# RN831X_RN861X_MCU register map
File version: v0.0.1
CPU: RN831X_RN861X_MCU r1p0, little endian, MPU, no FPU
Registers are 32-bit, read-write, reset 0x0 unless marked. A register's access mark holds for its fields unless they carry their own. Offsets are from the block's base; [hi:lo] are bit positions.

## LCSS_VCC_CORE0 — LCSS_VCC Module core0
Base 0x2010C000
0x00 PSW0 access not given — Security key register 0
  [15:0] PSW — Managed registers include LCSS_EN/LCSS_ASWH/LCSS_CTRL/LCSS_RCL_OS/LCSS_HFDLA_TH/LCSS_LFDLA_TH/LCSS_IE
0x04 PSW1 access not given — Security key register 1
  [15:0] PSW — Managed registers include LCSS_CLKSWH
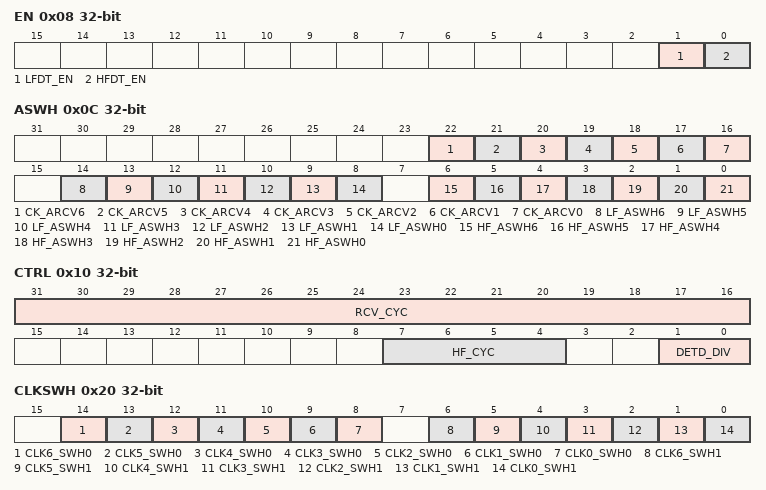
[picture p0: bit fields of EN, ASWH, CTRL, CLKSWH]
0x08 EN — Enable register
  [1] LFDT_EN — Low frequency abnormal detection enable
  [0] HFDT_EN — High frequency abnormal detection enable
0x0C ASWH — Auto switch configuration register
  [22] CK_ARCV6 — (System clock: LOSC to RCL) Enable automatic switch to source clock in normal frequency
  [21] CK_ARCV5 — (Infrared Clock: LOSC to RCL) Enable automatic switch to source clock in normal frequency
  [20] CK_ARCV4 — (LCD Clock: LOSC to RCL) Enable automatic switch to source clock in normal frequency
  [19] CK_ARCV3 — (LPUART Clock: LOSC to RCL) Enable automatic switch to source clock in normal frequency
  [18] CK_ARCV2 — (KBI Clock: LOSC to RCL) Enable automatic switch to source clock in normal frequency
  [17] CK_ARCV1 — (PLL source: LOSC to RCL) Enable automatic switch to source clock in normal frequency
  [16] CK_ARCV0 — (System clock: PLL to RCH) Enable automatic switch to backup clock in low frequency abnormality
  [14] LF_ASWH6 — (System clock: LOSC to RCL) Enable automatic switch to backup clock in low frequency abnormality
  [13] LF_ASWH5 — (Infrared Clock: LOSC to RCL) Enable automatic switch to backup clock in low frequency abnormality
  [12] LF_ASWH4 — (LCD Clock: LOSC to RCL) Enable automatic switch to backup clock in low frequency abnormality
  [11] LF_ASWH3 — (LPUART Clock: LOSC to RCL) Enable automatic switch to backup clock in low frequency abnormality
  [10] LF_ASWH2 — (KBI Clock: LOSC to RCL) Enable automatic switch to backup clock in low frequency abnormality
  [9] LF_ASWH1 — (PLL source: LOSC to RCL) Enable automatic switch to backup clock in low frequency abnormality
  [8] LF_ASWH0 — (System clock: PLL to RCH) Enable automatic switch to backup clock in low frequency abnormality
  [6] HF_ASWH6 — (System clock: LOSC to RCL) Enable automatic switch to backup clock in high frequency abnormality
  [5] HF_ASWH5 — (Infrared Clock: LOSC to RCL) Enable automatic switch to backup clock in high frequency abnormality
  [4] HF_ASWH4 — (LCD Clock: LOSC to RCL) Enable automatic switch to backup clock in high frequency abnormality
  [3] HF_ASWH3 — (LPUART Clock: LOSC to RCL) Enable automatic switch to backup clock in high frequency abnormality
  [2] HF_ASWH2 — (KBI Clock: LOSC to RCL) Enable automatic switch to backup clock in high frequency abnormality
  [1] HF_ASWH1 — (PLL source: LOSC to RCL) Enable automatic switch to backup clock in high frequency abnormality
  [0] HF_ASWH0 — (System clock: PLL to RCH) Enable automatic switch to backup clock in high frequency abnormality
0x10 CTRL — Control register
  [31:16] RCV_CYC — LOSC recovery time configuration
  [7:4] HF_CYC — High frequency/low frequency abnormality threshold
  [1:0] DETD_DIV — Clock frequency division configuration
    0=NONE (No Frequency division); 1=2 Frequency division; 2=4 Frequency division; 3=8 Frequency division
0x14 RCL_OS access not given — RCL32K frequency offset register
  [7:0] RCL_OS — This register is configurable only when LCSS_EN=0
0x18 HFDLA_TH access not given reset 0x3 — High frequency abnormal offset threshold configuration register
  [7:0] HFDLA_TH — This register is configurable only when LCSS_EN=0
0x1C LFDLA_TH access not given reset 0x31 — Low frequency abnormal offset threshold configuration register
  [7:0] LFDLA_TH — This register is configurable only when LCSS_EN=0
0x20 CLKSWH wo — Clock configuration register for software switch
  [14] CLK6_SWH0 — (System clock: RCL to LOSC) software switch to source clock
  [13] CLK5_SWH0 — (Infrared Clock: RCL to LOSC) software switch to source clock
  [12] CLK4_SWH0 — (LCD Clock: RCL to LOSC) software switch to source clock
  [11] CLK3_SWH0 — (LPUART Clock: RCL to LOSC) software switch to source clock
  [10] CLK2_SWH0 — (KBI Clock: RCL to LOSC) software switch to source clock
  [9] CLK1_SWH0 — (PLL source: RCL to LOSC) software switch to source clock
  [8] CLK0_SWH0 — (System clock: RCH to PLL) software switch to source clock
  [6] CLK6_SWH1 — (System clock: LOSC to RCL) software switch to backup clock
  [5] CLK5_SWH1 — (Infrared Clock: LOSC to RCL) software switch to backup clock
  [4] CLK4_SWH1 — (LCD Clock: LOSC to RCL) software switch to backup clock
  [3] CLK3_SWH1 — (LPUART Clock: LOSC to RCL) software switch to backup clock
  [2] CLK2_SWH1 — (KBI Clock: LOSC to RCL) software switch to backup clock
  [1] CLK1_SWH1 — (PLL source: LOSC to RCL) software switch to backup clock
  [0] CLK0_SWH1 — (System clock: PLL to RCH) software switch to backup clock
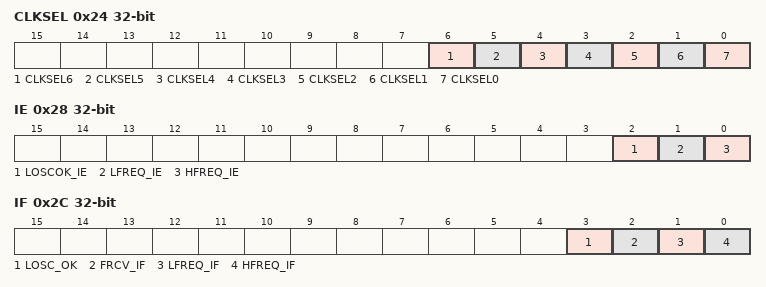
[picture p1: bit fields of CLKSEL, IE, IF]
0x24 CLKSEL ro — Clock selected register, indicate the selected clock
  [6] CLKSEL6 — (System clock: LOSC to RCL) Indicate the current clock selection, source clock or backup clock
  [5] CLKSEL5 — (Infrared Clock: LOSC to RCL) Indicate the current clock selection, source clock or backup clock
  [4] CLKSEL4 — (LCD Clock: LOSC to RCL) Indicate the current clock selection, source clock or backup clock
  [3] CLKSEL3 — (LPUART Clock: LOSC to RCL) Indicate the current clock selection, source clock or backup clock
  [2] CLKSEL2 — (KBI Clock: LOSC to RCL) Indicate the current clock selection, source clock or backup clock
  [1] CLKSEL1 — (PLL source: LOSC to RCL) Indicate the current clock selection, source clock or backup clock
  [0] CLKSEL0 — (System clock: PLL to RCH) Indicate the current clock selection, source clock or backup clock
0x28 IE — Interrupt enable register
  [2] LOSCOK_IE — LOSC clock is OK interrupt enable
  [1] LFREQ_IE — Clock low frequency abnormal interrupt enable
  [0] HFREQ_IE — Clock high frequency abnormal interrupt enable
0x2C IF access per field — Status register
  [3] LOSC_OK ro — Indicates the current LOSC clock frequency status
  [2] FRCV_IF rw write-1-clears — The flag for the normal (recovery) frequency event of the clock
  [1] LFREQ_IF rw write-1-clears — The flag for the low-frequency abnormal event of the clock
  [0] HFREQ_IF rw write-1-clears — The flag for the high-frequency abnormal event of the clock
0x30 HFREQ access not given — High frequency abnormal frequency register
  [7:0] HFREQ — Set maximum high frequency abnormal frequency value
0x34 LFREQ access not given — Low frequency abnormal frequency register
  [7:0] LFREQ — Set minimum low frequency abnormal frequency value
